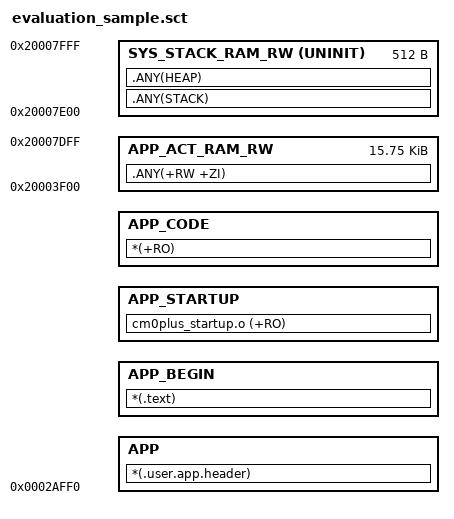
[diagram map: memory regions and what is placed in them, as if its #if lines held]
#! armcc -E
#include "..\inc\application\device_cfg.h"

; *************************************************************
; *** Scatter-Loading Description File generated by uVision ***
; *************************************************************

#if defined(MXD2660A_F256) | defined(MXD2660B_F256) | defined(MXD2660C_F256) 
    #ifdef RELEASE_DEFAULT_VERSION

        #define STACK_ADDR 0x00001FF0
        #define STACK_SIZE 0x00014800
        
        #define APP_ADDR   (STACK_ADDR +  STACK_SIZE + STACK_SIZE)
        #define APP_SIZE   (0x40000 - APP_ADDR - 0x400)
        
        #define BOOT_RAM_ADDR 0x20000000
        #define BOOT_RAM_SIZE 0x00000100
        
        #define LIB_RAM_ADR (BOOT_RAM_ADDR + BOOT_RAM_SIZE)
        #define LIB_RAM_SIZE 0x0004A00
        
        #define SYS_STACK_ADR 0x20007E00
        #define SYS_STACK_SIZE 0x200
        
        #define APP_RAM_ADR (LIB_RAM_ADR + LIB_RAM_SIZE)
        #define APP_RAM_SIZE (0x8000 - LIB_RAM_SIZE - BOOT_RAM_SIZE - SYS_STACK_SIZE)
        
    #endif
        
    #ifdef RELEASE_RAM_20KB_VERSION 
        #define STACK_ADDR 0x00001FF0
        #define STACK_SIZE 0x00014800
        
        #define APP_ADDR   (STACK_ADDR +  STACK_SIZE + STACK_SIZE)
        #define APP_SIZE   (0x40000 - APP_ADDR - 0x400)
        
        #define BOOT_RAM_ADDR 0x20000000
        #define BOOT_RAM_SIZE 0x00000100      
        
        #define LIB_RAM_ADR (BOOT_RAM_ADDR + BOOT_RAM_SIZE)
        #define LIB_RAM_SIZE 0x00003E00
        
        #define SYS_STACK_ADR 0x20007E00
        #define SYS_STACK_SIZE 0x200
        
        #define APP_RAM_ADR (LIB_RAM_ADR + LIB_RAM_SIZE)
        #define APP_RAM_SIZE (0x8000 - LIB_RAM_SIZE - BOOT_RAM_SIZE - SYS_STACK_SIZE)

    #endif
#endif


LOAD_APP APP_ADDR APP_SIZE   ; load region size_region
{
    APP  +0  {  ; 
        *(.user.app.header)
    }
    APP_BEGIN  +0  {  ; 
        *(.text)
    }
    APP_STARTUP  +0  {  ; 
        cm0plus_startup.o (+RO)
    }
    APP_CODE +0 {
        *(+RO)
    }
              
    APP_ACT_RAM_RW APP_RAM_ADR APP_RAM_SIZE  {  ; RW data  h
        .ANY(+RW +ZI)
    }
    
    SYS_STACK_RAM_RW SYS_STACK_ADR UNINIT SYS_STACK_SIZE  {  ; RW data  
        .ANY(STACK)
        .ANY(HEAP)
    }
    
}

